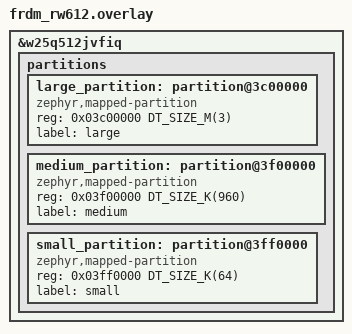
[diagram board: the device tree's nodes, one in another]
/*
 * Copyright 2025 NXP
 *
 * SPDX-License-Identifier: Apache-2.0
 */

/delete-node/ &storage_partition;

&w25q512jvfiq {
	partitions {
		large_partition: partition@3c00000 {
			compatible = "zephyr,mapped-partition";
			reg = <0x03c00000 DT_SIZE_M(3)>;
			label = "large";
		};

		medium_partition: partition@3f00000 {
			compatible = "zephyr,mapped-partition";
			reg = <0x03f00000 DT_SIZE_K(960)>;
			label = "medium";
		};

		small_partition: partition@3ff0000 {
			compatible = "zephyr,mapped-partition";
			reg = <0x03ff0000 DT_SIZE_K(64)>;
			label = "small";
		};
	};
};
